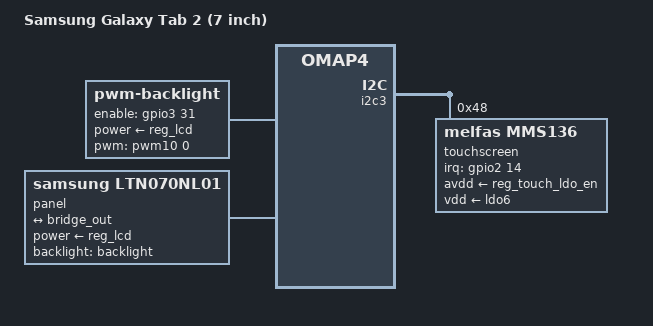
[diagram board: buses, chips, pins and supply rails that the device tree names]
// SPDX-License-Identifier: (GPL-2.0 OR MIT)
/dts-v1/;

#include "omap4-samsung-espresso-common.dtsi"

/ {
	model = "Samsung Galaxy Tab 2 (7 inch)";
	compatible = "samsung,espresso7", "ti,omap4430", "ti,omap4";

	backlight: backlight {
		compatible = "pwm-backlight";
		pinctrl-names = "default";
		pinctrl-0 = <&backlight_pins>;
		pwms = <&pwm10 0 1200 0>;
		power-supply = <&reg_lcd>;
		enable-gpios = <&gpio3 31 GPIO_ACTIVE_HIGH>;
		brightness-levels = <0 4 8 16 32 64 128 255>;
		default-brightness-level = <2>;
	};

	panel {
		compatible = "samsung,ltn070nl01", "panel-lvds";
		power-supply = <&reg_lcd>;
		width-mm = <154>;
		height-mm = <90>;
		data-mapping = "vesa-24";
		backlight = <&backlight>;

		panel-timing {
			clock-frequency = <47255554>;

			hback-porch = <210>;
			hactive = <1024>;
			hfront-porch = <186>;
			hsync-len = <50>;

			vback-porch = <11>;
			vactive = <600>;
			vfront-porch = <24>;
			vsync-len = <10>;

			hsync-active = <0>;
			vsync-active = <0>;
			de-active = <1>;
			pixelclk-active = <1>;
			syncclk-active = <0>;
		};

		port {
			panel_in: endpoint {
				remote-endpoint = <&bridge_out>;
			};
		};
	};
};

&i2c3 {
	touchscreen@48 {
		compatible = "melfas,mms136";
		reg = <0x48>;
		interrupt-parent = <&gpio2>;
		interrupts = <14 IRQ_TYPE_EDGE_FALLING>;
		touchscreen-size-x = <1024>;
		touchscreen-size-y = <600>;
		pinctrl-names = "default";
		pinctrl-0 = <&touch_pins>;
		avdd-supply = <&reg_touch_ldo_en>;
		vdd-supply = <&ldo6>;
	};
};
